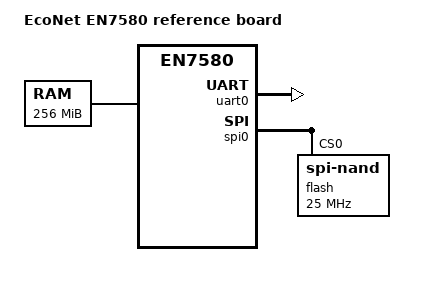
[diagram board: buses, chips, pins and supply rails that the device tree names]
// SPDX-License-Identifier: GPL-2.0+
/dts-v1/;

#include "econet,en7580.dtsi"

/ {
	model = "EcoNet EN7580 reference board";
	compatible = "econet,en7580-reference", "econet,en7580", "airoha,en7580";

	/* The RAM-training stage replaces this size during U-Boot startup. */
	memory@0 {
		device_type = "memory";
		reg = <0x00000000 0x10000000>;
	};

	chosen {
		stdout-path = "serial0:115200n8";
	};
};

&uart0 {
	status = "okay";
};

&spi0 {
	status = "okay";

	flash@0 {
		compatible = "spi-nand";
		reg = <0>;
		spi-max-frequency = <25000000>;
		spi-tx-bus-width = <1>;
		spi-rx-bus-width = <1>;
	};
};
